# ISP_CSIPHY2 register map
Vendor: Texas Instruments
Peripheral module from a debugger description file (folder omap36xx).
Registers are 32-bit, access per field, reset 0x427 unless marked. A register's access mark holds for its fields unless they carry their own. Offsets are as the file gives them; lines under a group give offsets from that group; [hi:lo] are bit positions; {n}, {i} and the like mark numbered series; 'fields as' and 'values as' point back to an identical list; <NAME> marks a mode.

## ISP_CSIPHY2
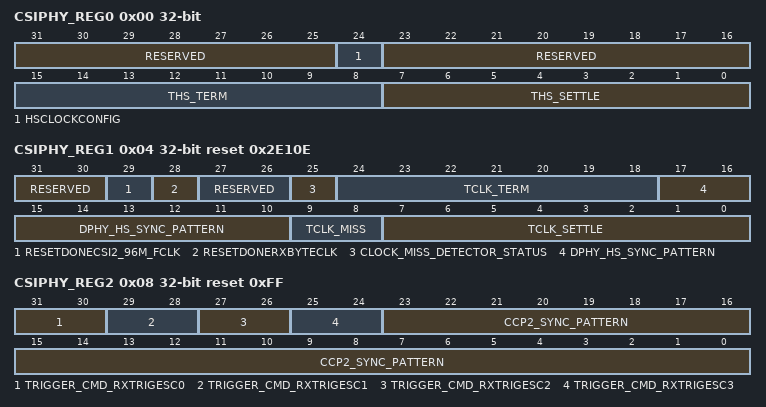
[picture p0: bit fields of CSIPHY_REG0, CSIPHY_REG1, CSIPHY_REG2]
0x00 CSIPHY_REG0 access not given — First Register
  [31:25] RESERVED — Write 0s for future compatibility. Read returns 0. (access NA)
  [24] HSCLOCKCONFIG rw — Disable clock missing detector
  [23:16] RESERVED ro — Write 0s for future compatibility. Read returns 0.
  [15:8] THS_TERM rw — Ths-term timing parameter in multiples of CSI2_96M_FCLK period.Requirement from DSI_PHY spec = (Dn Voltage 450 mV) –35 ns + 4 UI. Effective time for enabling termination = synchonizer delay + timer delay + LPRx delay + combinatorial routing delay ~ (1–2)*DDRCLK + Ths-term + ~ (1–15) ns. Programmed value = ceil(12.5 ns/DDRClk period)–1. Default value: 4 for 400 MHz. 20 percent clock frequency tolerance.
  [7:0] THS_SETTLE rw — Ths-settle timing parameter in multiples of DDR clock period.Derived requirement from DSI_PHY spec = (90 ns + 6 UI) – (145 ns + 10 UI). Effective Ths-settle seen on the line (starting to look for sync pattern) = synchonizer delay + timer delay + LPRx delay + combinatorial routing delay – pipeline delay in HS data path. ~ (1–2)*DDRCLK + Ths-settle + ~ (1–15) ns – 1*DDRClk Programmed value = ceil(90 ns/DDR clock period)+3. Default value: 39 for 400 MHz.
0x04 CSIPHY_REG1 reset 0x2E10E (reset mask 0xCFFFFFFF) — Second Register
  [31:30] RESERVED ro — Write 0s for future compatibility. Read returns 0.
  [29] RESETDONECSI2_96M_FCLK ro — Reset Done flag for the CSI2_96M_FCLK domainRead 0x0: Reset in progress Read 0x1: Reset completed
  [28] RESETDONERXBYTECLK ro — Reset Done flag for the RxByteClkHS clock domain Read 0x0: Reset in progress Read 0x1: Reset completed
  [27:26] RESERVED rw — Write 0s for future compatibility. Read returns 0.
  [25] CLOCK_MISS_DETECTOR_STATUS ro — 1:Error in clock missing detector. 0:Clock missing detector successful
  [24:18] TCLK_TERM rw — Tclk-term timing parameter in multiples of CSI2_96M_FCLK period.Requirement from DSI_PHY spec = (Dn Voltage 450 mV) –55 ns. Effective time for enabling termination = synchonizer delay + timer delay + LPRx delay + combinatorial routing delay ~ (1–2)*CSI2_96M_FCLK + Tclk-term + ~ (1–15) ns. Programmed value = ceil(9.5 ns/CSI2_96M_FCLK period)–1). Default value: 0 for 96 MHz. 5 percent clock frequency tolerance.
  [17:10] DPHY_HS_SYNC_PATTERN rw — DPHY mode HS sync pattern in byte order(reverse of received order)
  [9:8] TCLK_MISS rw — Tclk-miss timing parameter in multiples of CSI2_96M_FCLK periodProgrammed value = ceil(15 ns/CSI2_96M_FCLK period)–1 Default value: 1 for 96 MHz
  [7:0] TCLK_SETTLE rw — Tclk-settle timing parameter in multiples of CSI2_96M_FCLK period.Derived requirement from DSI_PHY spec = 145 ns –435 ns. Effective Ths-settle = synchonizer delay + timer delay + LPRx delay + combinatorial routing delay ~ (1–2)*CSI2_96M_FCLK + Tclk-settle + ~ (1–15) ns. Programmed value = max(3, ceil(155 ns/CSI2_96M_FCLK period)–1). Default value: 14 for 96 MHz. 5 percent clock frequency tolerance
0x08 CSIPHY_REG2 reset 0xFF — Third register
  [31-2n:30-2n] TRIGGER_CMD_RXTRIGESC{n} rw (n=0..3) — Mapping of Trigger escape entry command to PPI output RXTRIGGERESC{n}
  [23:0] CCP2_SYNC_PATTERN ro — CCP2 mode sync pattern in byte order
